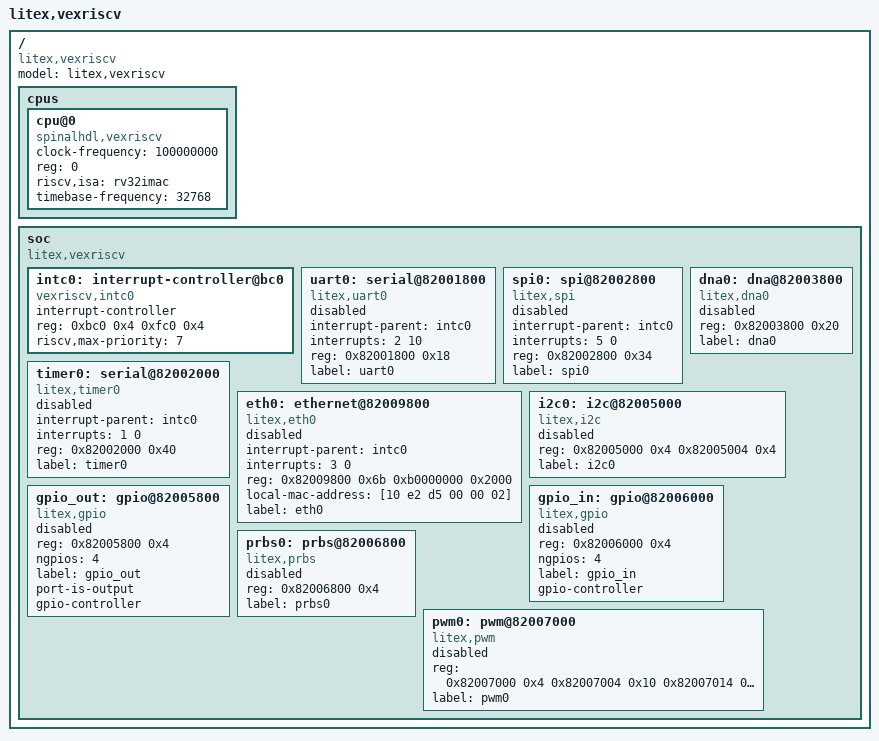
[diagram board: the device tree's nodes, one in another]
/*
 * Copyright (c) 2018 - 2019 Antmicro <www.antmicro.com>
 *
 * SPDX-License-Identifier: Apache-2.0
 */

/ {
	#address-cells = <1>;
	#size-cells = <1>;
	compatible = "litex,vexriscv", "litex-dev";
	model = "litex,vexriscv";
	cpus {
		#address-cells = <1>;
		#size-cells = <0>;
		cpu@0 {
			clock-frequency = <100000000>;
			compatible = "spinalhdl,vexriscv", "riscv";
			device_type = "cpu";
			reg = <0>;
			riscv,isa = "rv32imac";
			status = "okay";
			timebase-frequency = <32768>;
		};
	};
	soc {
		#address-cells = <1>;
		#size-cells = <1>;
		compatible = "litex,vexriscv";
		ranges;
		intc0: interrupt-controller@bc0 {
			#interrupt-cells = <2>;
			compatible = "vexriscv,intc0";
			interrupt-controller;
			reg = <0xbc0 0x4 0xfc0 0x4>;
			reg-names = "irq_mask", "irq_pending";
			riscv,max-priority = <7>;
		};
		uart0: serial@82001800 {
			compatible = "litex,uart0";
			interrupt-parent = <&intc0>;
			interrupts = <2 10>;
			reg = <0x82001800 0x18>;
			reg-names = "control";
			label = "uart0";
			status = "disabled";
		};
		spi0: spi@82002800 {
			compatible = "litex,spi";
			interrupt-parent = <&intc0>;
			interrupts = <5 0>;
			reg = <0x82002800 0x34>;
			reg-names = "control";
			label = "spi0";
			status = "disabled";
			#address-cells = <1>;
			#size-cells = <0>;
		};
		timer0: serial@82002000 {
			compatible = "litex,timer0";
			interrupt-parent = <&intc0>;
			interrupts = <1 0>;
			reg = <0x82002000 0x40>;
			reg-names = "control";
			label = "timer0";
			status = "disabled";
		};
		eth0: ethernet@82009800 {
			compatible = "litex,eth0";
			interrupt-parent = <&intc0>;
			interrupts = <3 0>;
			reg = <0x82009800 0x6b 0xb0000000 0x2000>;
			local-mac-address = [10 e2 d5 00 00 02];
			reg-names = "control", "buffers";
			label = "eth0";
			status = "disabled";
		};
		dna0: dna@82003800 {
			compatible = "litex,dna0";
			/* DNA data is 57-bits long,
			so it requires 8 bytes.
			In LiteX each 32-bit register holds
			only a single byte of meaningful data,
			hence 8 registers. */
			reg = <0x82003800 0x20>;
			reg-names = "mem";
			label = "dna0";
			status = "disabled";
		};
		i2c0: i2c@82005000 {
			compatible = "litex,i2c";
			reg = <0x82005000 0x4 0x82005004 0x4>;
			reg-names = "write", "read";
			label = "i2c0";
			#address-cells = <1>;
			#size-cells = <0>;
			status = "disabled";
		};
		gpio_out: gpio@82005800 {
			compatible = "litex,gpio";
			reg = <0x82005800 0x4>;
			reg-names = "control";
			ngpios = <4>;
			label = "gpio_out";
			port-is-output;
			status = "disabled";
			gpio-controller;
			#gpio-cells = <2>;
		};
		gpio_in: gpio@82006000 {
			compatible = "litex,gpio";
			reg = <0x82006000 0x4>;
			reg-names = "control";
			ngpios = <4>;
			label = "gpio_in";
			status = "disabled";
			gpio-controller;
			#gpio-cells = <2>;
		};
		prbs0: prbs@82006800 {
			compatible = "litex,prbs";
			reg = <0x82006800 0x4>;
			reg-names = "status";
			label = "prbs0";
			status = "disabled";
		};
		pwm0: pwm@82007000 {
			compatible = "litex,pwm";
			reg = <0x82007000 0x4 0x82007004 0x10 0x82007014 0x10>;
			reg-names = "enable", "width", "period";
			label = "pwm0";
			status = "disabled";
			#pwm-cells = <2>;
		};
	};
};
